# TMS320F28069 register map
Vendor: Texas Instruments; Series: C2000 F2806x; File version: 0.2.0-generated
Registers are 16-bit, read-write, reset 0x0 unless marked. A register's access mark holds for its fields unless they carry their own. Offsets are from the block's base; [hi:lo] are bit positions; {n}, {i} and the like mark numbered series.

## USB0 — USB Registers
Base 0x00008000
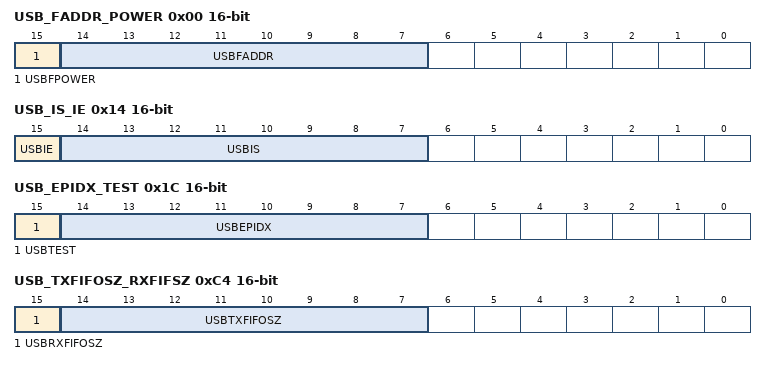
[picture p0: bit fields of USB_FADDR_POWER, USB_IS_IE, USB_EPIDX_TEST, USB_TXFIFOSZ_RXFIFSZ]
0x00 USB_FADDR_POWER — USB FADDR and POWER
  [15] USBFPOWER — USB Power
  [14:7] USBFADDR — USB Device Functional Address
0x04 USBTXIS — USB Transmit Interrupt Status
0x08 USBRXIS — USB Receive Interrupt Status
0x0C USBTXIE — USB Transmit Interrupt Enable
0x10 USBRXIE — USB Receive Interrupt Enable
0x14 USB_IS_IE — USB IS and IE
  [15] USBIE — USB Interrupt Enable
  [14:7] USBIS — USB General Interrupt Status
0x18 USBFRAME — USB Frame Value
0x1C USB_EPIDX_TEST — USB EPIDX and TEST
  [15] USBTEST — USB Test Mode
  [14:7] USBEPIDX — USB Endpoint Index
{0x40+8i} USBFIFO{i} 32-bit (i=0..3) — USB FIFO Endpoint {i}
0xC0 USBDEVCTL
  [14:7] USBDEVCTL — USB Endpoint Index
0xC4 USB_TXFIFOSZ_RXFIFSZ — USB TXFIFOSZ and RXFIFSZ
  [15] USBRXFIFOSZ — USB Receive Dynamic FIFO Sizing
  [14:7] USBTXFIFOSZ — USB Transmit Dynamic FIFO Sizing
0xC8 USBTXFIFOADD — USB Transmit FIFO Start Address
0xCC USBRXFIFOADD — USB Receive FIFO Start Address
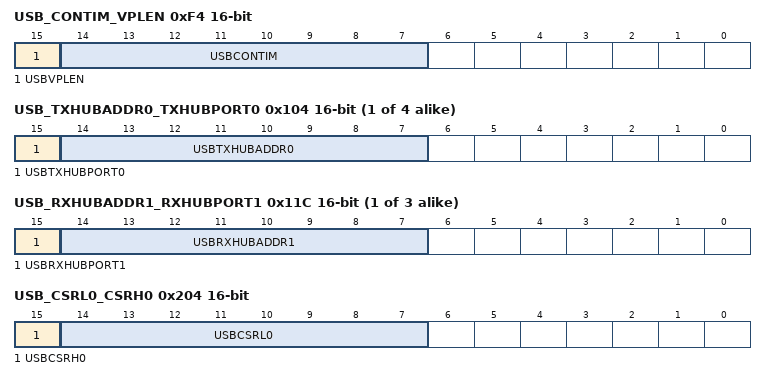
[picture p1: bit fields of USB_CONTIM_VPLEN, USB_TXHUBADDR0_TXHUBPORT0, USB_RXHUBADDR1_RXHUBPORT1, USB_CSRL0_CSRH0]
0xF4 USB_CONTIM_VPLEN — USB CONTIM and VPLEN
  [15] USBVPLEN — USB OTG VBUS Pulse Timing
  [14:7] USBCONTIM — USB Connect Timin
0xF8 USBFSEOF — USBFSEOFF
  [15] USBFSEOF — USB Full-Speed Last Transaction to End of Frame Timing
0xFC USBLSEOF
  [14:7] USBLSEOF — USB Low-Speed Last Transaction to End of Frame Timing
{0x100+0x10*i} USBTXFUNCADDR{i} (i=0..3)
  [14:7] USBTXFUNCADDR{i} — USB Transmit Functional Address Endpoint {i}
{0x104+0x10*i} USB_TXHUBADDR{i}_TXHUBPORT{i} (i=0..3) — USB TXHUBADDR{i} and TXHUBPORT{i}
  [15] USBTXHUBPORT{i} — USB Transmit Hub Port Endpoint {i}
  [14:7] USBTXHUBADDR{i} — USB Transmit Hub Address Endpoint {i}
{0x108+0x10*i} USBRXFUNCADDR{i} (i=1..3)
  [14:7] USBTXFUNCADDR{i} — USB Receive Functional Address Endpoint {i}
{0x10C+0x10*i} USB_RXHUBADDR{i}_RXHUBPORT{i} (i=1..3) — USB RXHUBADDR{i} and RXHUBPORT{i}
  [15] USBRXHUBPORT{i} — USB Receive Hub Port Endpoint {i}
  [14:7] USBRXHUBADDR{i} — USB Receive Hub Address Endpoint {i}
0x204 USB_CSRL0_CSRH0 — USB CSRL0 and CSRH0
  [15] USBCSRH0 — USB Control and Status Endpoint 0 High
  [14:7] USBCSRL0 — USB Control and Status Endpoint 0 Low
0x20C USBCOUNT0
  [14:7] USBCOUNT0 — USB Receive Byte Count Endpoint 0
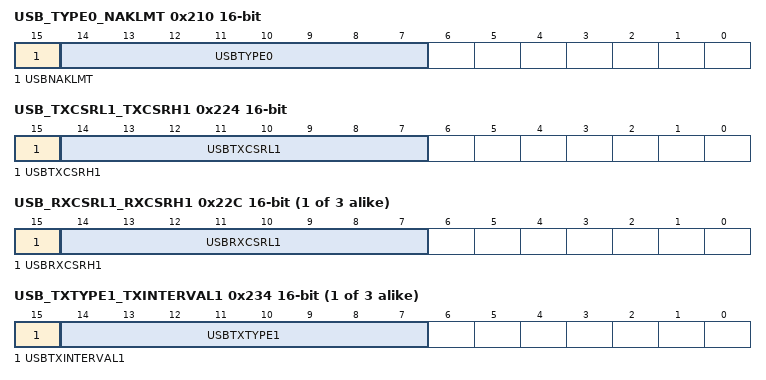
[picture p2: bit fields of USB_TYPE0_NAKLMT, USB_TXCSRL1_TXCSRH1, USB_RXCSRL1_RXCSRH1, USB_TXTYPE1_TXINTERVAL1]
0x210 USB_TYPE0_NAKLMT — USB TYPE0 and NAKLMT
  [15] USBNAKLMT — USB NAK Limit
  [14:7] USBTYPE0 — USB Type Endpoint 0
{0x200+0x20*i} USBTXMAXP{i} (i=1..3) — USB Maximum Transmit Data Endpoint {i}
0x224 USB_TXCSRL1_TXCSRH1 — USB TXCSRL1 and TXCSRH1
  [15] USBTXCSRH1 — USB Transmit Control and Status Endpoint 1 High
  [14:7] USBTXCSRL1 — USB Transmit Control and Status Endpoint 1 Low
{0x208+0x20*i} USBRXMAXP{i} (i=1..3) — USB Maximum Receive Data Endpoint {i}
{0x20C+0x20*i} USB_RXCSRL{i}_RXCSRH{i} (i=1..3) — USB RXCSRL{i} and RXCSRH{i}
  [15] USBRXCSRH{i} — USB Receive Control and Status Endpoint {i} High
  [14:7] USBRXCSRL{i} — USB Receive Control and Status Endpoint {i} Low
{0x210+0x20*i} USBRXCOUNT{i} (i=1..3) — USB Receive Byte Count Endpoint {i}
{0x214+0x20*i} USB_TXTYPE{i}_TXINTERVAL{i} (i=1..3) — USB TXTYPE{i} and TXINTERVAL{i}
  [15] USBTXINTERVAL{i} — USB Host Transmit Interval Endpoint {i}
  [14:7] USBTXTYPE{i} — USB Host Transmit Configure Type Endpoint {i}
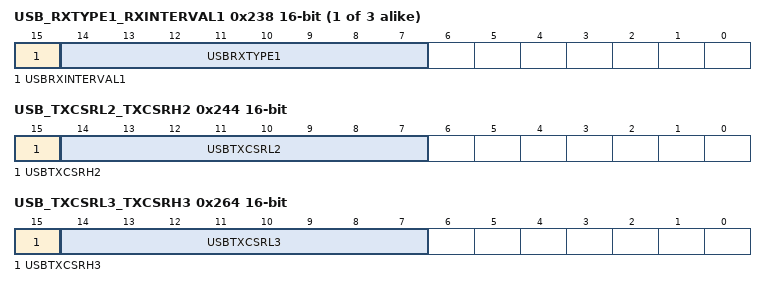
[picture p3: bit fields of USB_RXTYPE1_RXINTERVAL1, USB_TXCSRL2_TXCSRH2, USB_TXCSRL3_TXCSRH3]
{0x218+0x20*i} USB_RXTYPE{i}_RXINTERVAL{i} (i=1..3) — USB RXTYPE{i} and RXINTERVAL{i}
  [15] USBRXINTERVAL{i} — USB Host Receive Interval Endpoint {i}
  [14:7] USBRXTYPE{i} — USB Host Receive Configure Type Endpoint {i}
0x244 USB_TXCSRL2_TXCSRH2 — USB TXCSRL2 and TXCSRH2
  [15] USBTXCSRH2 — USB Transmit Control and Status Endpoint 2 High
  [14:7] USBTXCSRL2 — USB Transmit Control and Status Endpoint 2 Low
0x264 USB_TXCSRL3_TXCSRH3 — USB TXCSRL32 and TXCSRH3
  [15] USBTXCSRH3 — USB Transmit Control and Status Endpoint 3 High
  [14:7] USBTXCSRL3 — USB Transmit Control and Status Endpoint 3 Low
{0x600+8i} USBRQPKTCOUNT{i} (i=1..3) — USB Request Packet Count in Block Transfer Endpoint {i}
0x680 USBRXDPKTBUFDIS — USB Receive Double Packet Buffer Disable
0x684 USBTXDPKTBUFDIS — USB Transmit Double Packet Buffer Disable
0x800 USBEPC 32-bit — USB External Power Control
0x808 USBEPCRIS 32-bit — USB External Power Control Raw Interrupt Status
0x810 USBEPCIM 32-bit — USB External Power Control Interrupt Mask
0x818 USBEPCISC 32-bit — USB External Power Control Interrupt Status and Clear
0x820 USBDRRIS 32-bit — USB Device RESUME Raw Interrupt Status
0x828 USBDRIM 32-bit — USB Device RESUME Interrupt Mask
0x830 USBDRISC 32-bit — USB Device RESUME Interrupt Status and Clear
0x838 USBGPCS 32-bit — USB General-Purpose Control and Status
0x860 USBVDC 32-bit — USB VBUS Droop Control
0x868 USBVDCRIS 32-bit — USB VBUS Droop Control Raw Interrupt Status
0x870 USBVDCIM 32-bit — USB VBUS Droop Control Interrupt Mask
0x878 USBVDCISC 32-bit — USB VBUS Droop Control Interrupt Status and Clear
0x888 USBIDVRIS 32-bit — USB ID Valid Detect Raw Interrupt Status
0x890 USBIDVIM 32-bit — USB ID Valid Detect Interrupt Mask
0x898 USBIDVISC 32-bit — USB ID Valid Detect Interrupt Status and Clear
0x8A0 USBDMASEL 32-bit — USB DMA Select
